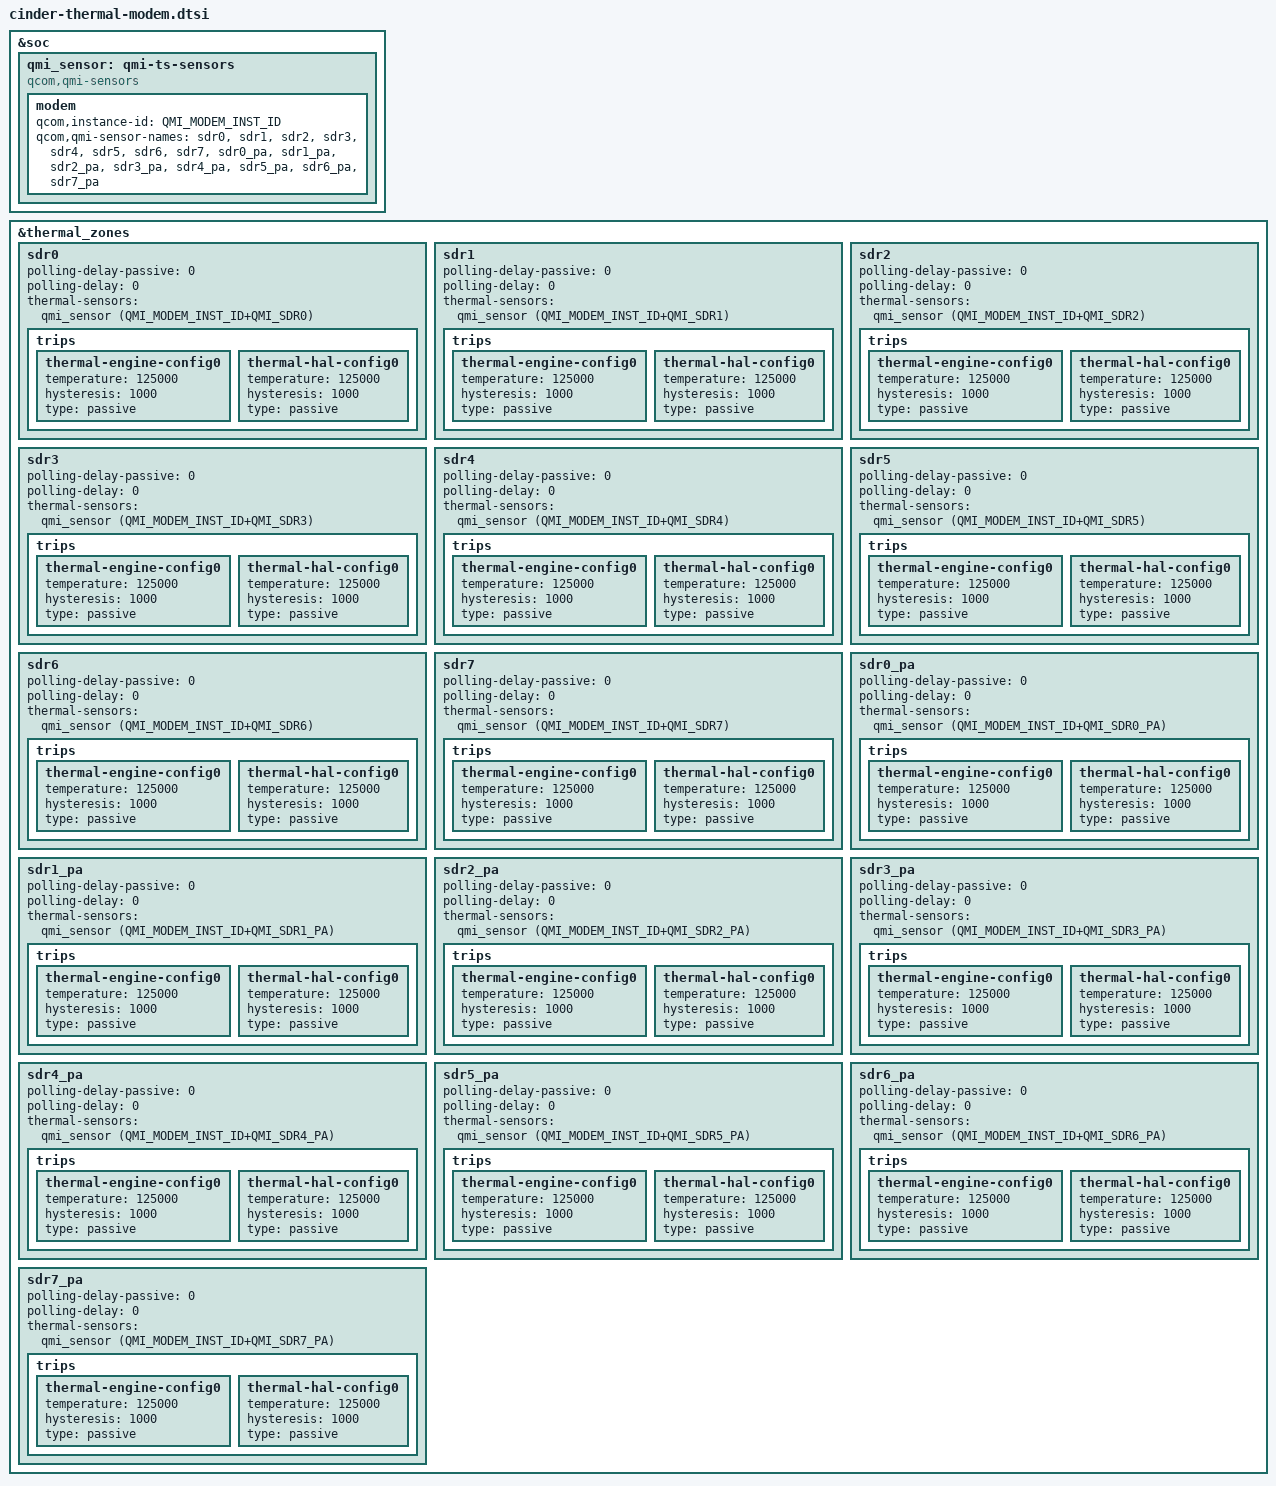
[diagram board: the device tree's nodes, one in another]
#include <dt-bindings/thermal/thermal_qti.h>

&soc {
	qmi_sensor: qmi-ts-sensors {
		compatible = "qcom,qmi-sensors";
		#thermal-sensor-cells = <1>;

		modem {
			qcom,instance-id = <QMI_MODEM_INST_ID>;
			qcom,qmi-sensor-names = "sdr0",
						"sdr1",
						"sdr2",
						"sdr3",
						"sdr4",
						"sdr5",
						"sdr6",
						"sdr7",
						"sdr0_pa",
						"sdr1_pa",
						"sdr2_pa",
						"sdr3_pa",
						"sdr4_pa",
						"sdr5_pa",
						"sdr6_pa",
						"sdr7_pa";
		};
	};
};

&thermal_zones {
	sdr0 {
		polling-delay-passive = <0>;
		polling-delay = <0>;
		thermal-sensors = <&qmi_sensor
				(QMI_MODEM_INST_ID+QMI_SDR0)>;
		trips {
			thermal-engine-config0 {
				temperature = <125000>;
				hysteresis = <1000>;
				type = "passive";
			};

			thermal-hal-config0 {
				temperature = <125000>;
				hysteresis = <1000>;
				type = "passive";
			};
		};
	};

	sdr1 {
		polling-delay-passive = <0>;
		polling-delay = <0>;
		thermal-sensors = <&qmi_sensor
				(QMI_MODEM_INST_ID+QMI_SDR1)>;
		trips {
			thermal-engine-config0 {
				temperature = <125000>;
				hysteresis = <1000>;
				type = "passive";
			};

			thermal-hal-config0 {
				temperature = <125000>;
				hysteresis = <1000>;
				type = "passive";
			};
		};
	};

	sdr2 {
		polling-delay-passive = <0>;
		polling-delay = <0>;
		thermal-sensors = <&qmi_sensor
				(QMI_MODEM_INST_ID+QMI_SDR2)>;
		trips {
			thermal-engine-config0 {
				temperature = <125000>;
				hysteresis = <1000>;
				type = "passive";
			};

			thermal-hal-config0 {
				temperature = <125000>;
				hysteresis = <1000>;
				type = "passive";
			};
		};
	};

	sdr3 {
		polling-delay-passive = <0>;
		polling-delay = <0>;
		thermal-sensors = <&qmi_sensor
				(QMI_MODEM_INST_ID+QMI_SDR3)>;
		trips {
			thermal-engine-config0 {
				temperature = <125000>;
				hysteresis = <1000>;
				type = "passive";
			};

			thermal-hal-config0 {
				temperature = <125000>;
				hysteresis = <1000>;
				type = "passive";
			};
		};
	};

	sdr4 {
		polling-delay-passive = <0>;
		polling-delay = <0>;
		thermal-sensors = <&qmi_sensor
				(QMI_MODEM_INST_ID+QMI_SDR4)>;
		trips {
			thermal-engine-config0 {
				temperature = <125000>;
				hysteresis = <1000>;
				type = "passive";
			};

			thermal-hal-config0 {
				temperature = <125000>;
				hysteresis = <1000>;
				type = "passive";
			};
		};
	};

	sdr5 {
		polling-delay-passive = <0>;
		polling-delay = <0>;
		thermal-sensors = <&qmi_sensor
				(QMI_MODEM_INST_ID+QMI_SDR5)>;
		trips {
			thermal-engine-config0 {
				temperature = <125000>;
				hysteresis = <1000>;
				type = "passive";
			};

			thermal-hal-config0 {
				temperature = <125000>;
				hysteresis = <1000>;
				type = "passive";
			};
		};
	};

	sdr6 {
		polling-delay-passive = <0>;
		polling-delay = <0>;
		thermal-sensors = <&qmi_sensor
				(QMI_MODEM_INST_ID+QMI_SDR6)>;
		trips {
			thermal-engine-config0 {
				temperature = <125000>;
				hysteresis = <1000>;
				type = "passive";
			};

			thermal-hal-config0 {
				temperature = <125000>;
				hysteresis = <1000>;
				type = "passive";
			};
		};
	};

	sdr7 {
		polling-delay-passive = <0>;
		polling-delay = <0>;
		thermal-sensors = <&qmi_sensor
				(QMI_MODEM_INST_ID+QMI_SDR7)>;
		trips {
			thermal-engine-config0 {
				temperature = <125000>;
				hysteresis = <1000>;
				type = "passive";
			};

			thermal-hal-config0 {
				temperature = <125000>;
				hysteresis = <1000>;
				type = "passive";
			};
		};
	};

	sdr0_pa {
		polling-delay-passive = <0>;
		polling-delay = <0>;
		thermal-sensors = <&qmi_sensor
				(QMI_MODEM_INST_ID+QMI_SDR0_PA)>;
		trips {
			thermal-engine-config0 {
				temperature = <125000>;
				hysteresis = <1000>;
				type = "passive";
			};

			thermal-hal-config0 {
				temperature = <125000>;
				hysteresis = <1000>;
				type = "passive";
			};
		};
	};

	sdr1_pa {
		polling-delay-passive = <0>;
		polling-delay = <0>;
		thermal-sensors = <&qmi_sensor
				(QMI_MODEM_INST_ID+QMI_SDR1_PA)>;
		trips {
			thermal-engine-config0 {
				temperature = <125000>;
				hysteresis = <1000>;
				type = "passive";
			};

			thermal-hal-config0 {
				temperature = <125000>;
				hysteresis = <1000>;
				type = "passive";
			};
		};
	};

	sdr2_pa {
		polling-delay-passive = <0>;
		polling-delay = <0>;
		thermal-sensors = <&qmi_sensor
		(QMI_MODEM_INST_ID+QMI_SDR2_PA)>;
		trips {
			thermal-engine-config0 {
				temperature = <125000>;
				hysteresis = <1000>;
				type = "passive";
			};

			thermal-hal-config0 {
				temperature = <125000>;
				hysteresis = <1000>;
				type = "passive";
			};
		};
	};

	sdr3_pa {
		polling-delay-passive = <0>;
		polling-delay = <0>;
		thermal-sensors = <&qmi_sensor
				(QMI_MODEM_INST_ID+QMI_SDR3_PA)>;
		trips {
			thermal-engine-config0 {
				temperature = <125000>;
				hysteresis = <1000>;
				type = "passive";
			};

			thermal-hal-config0 {
				temperature = <125000>;
				hysteresis = <1000>;
				type = "passive";
			};
		};
	};

	sdr4_pa {
		polling-delay-passive = <0>;
		polling-delay = <0>;
		thermal-sensors = <&qmi_sensor
				(QMI_MODEM_INST_ID+QMI_SDR4_PA)>;
		trips {
			thermal-engine-config0 {
				temperature = <125000>;
				hysteresis = <1000>;
				type = "passive";
			};

			thermal-hal-config0 {
				temperature = <125000>;
				hysteresis = <1000>;
				type = "passive";
			};
		};
	};

	sdr5_pa {
		polling-delay-passive = <0>;
		polling-delay = <0>;
		thermal-sensors = <&qmi_sensor
				(QMI_MODEM_INST_ID+QMI_SDR5_PA)>;
		trips {
			thermal-engine-config0 {
				temperature = <125000>;
				hysteresis = <1000>;
				type = "passive";
			};

			thermal-hal-config0 {
				temperature = <125000>;
				hysteresis = <1000>;
				type = "passive";
			};
		};
	};

	sdr6_pa {
		polling-delay-passive = <0>;
		polling-delay = <0>;
		thermal-sensors = <&qmi_sensor
				(QMI_MODEM_INST_ID+QMI_SDR6_PA)>;
		trips {
			thermal-engine-config0 {
				temperature = <125000>;
				hysteresis = <1000>;
				type = "passive";
			};

			thermal-hal-config0 {
				temperature = <125000>;
				hysteresis = <1000>;
				type = "passive";
			};
		};
	};

	sdr7_pa {
		polling-delay-passive = <0>;
		polling-delay = <0>;
		thermal-sensors = <&qmi_sensor
				(QMI_MODEM_INST_ID+QMI_SDR7_PA)>;
		trips {
			thermal-engine-config0 {
				temperature = <125000>;
				hysteresis = <1000>;
				type = "passive";
			};

			thermal-hal-config0 {
				temperature = <125000>;
				hysteresis = <1000>;
				type = "passive";
			};
		};
	};
};

